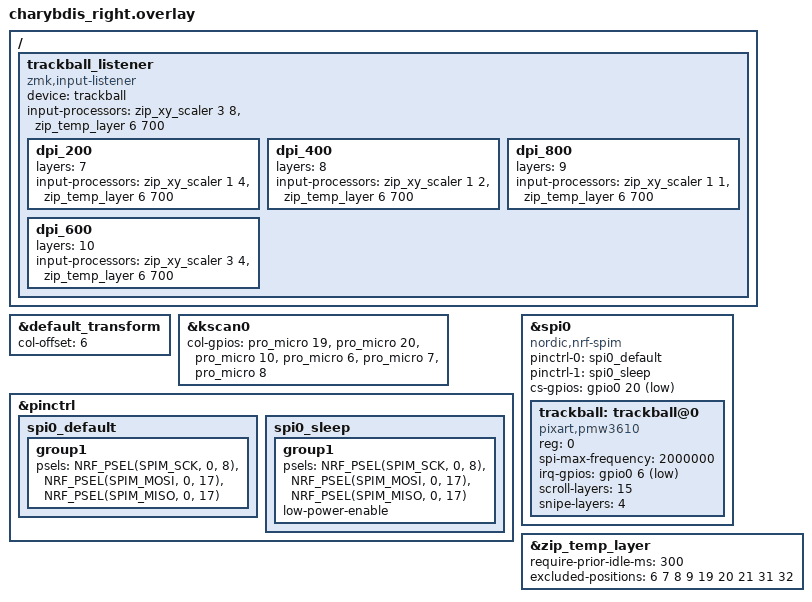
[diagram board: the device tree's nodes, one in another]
/*
 * Copyright (c) 2020 ZMK Contributors
 *
 * SPDX-License-Identifier: MIT
 */
 
#include "charybdis.dtsi"
#include <input/processors.dtsi>

&default_transform {
    col-offset = <6>;
};

&kscan0 {
	col-gpios
		= <&pro_micro 19 (GPIO_ACTIVE_HIGH | GPIO_PULL_DOWN)>
		, <&pro_micro 20 (GPIO_ACTIVE_HIGH | GPIO_PULL_DOWN)>
		, <&pro_micro 10 (GPIO_ACTIVE_HIGH | GPIO_PULL_DOWN)>
		, <&pro_micro 6 (GPIO_ACTIVE_HIGH | GPIO_PULL_DOWN)>
		, <&pro_micro 7 (GPIO_ACTIVE_HIGH | GPIO_PULL_DOWN)>
		, <&pro_micro 8 (GPIO_ACTIVE_HIGH | GPIO_PULL_DOWN)>
		;
};

// PMW3610 on the right half alongside the central. Pin/orientation values are
// retained from upstream and remain hardware assumptions to verify.
#include <dt-bindings/gpio/gpio.h>

&pinctrl {
    spi0_default: spi0_default {
        group1 {
            psels = <NRF_PSEL(SPIM_SCK, 0, 8)>,
                <NRF_PSEL(SPIM_MOSI, 0, 17)>,
                <NRF_PSEL(SPIM_MISO, 0, 17)>;
        };
    };
    spi0_sleep: spi0_sleep {
        group1 {
            psels = <NRF_PSEL(SPIM_SCK, 0, 8)>,
                <NRF_PSEL(SPIM_MOSI, 0, 17)>,
                <NRF_PSEL(SPIM_MISO, 0, 17)>;
            low-power-enable;
        };
    };
};

&spi0 {
    status = "okay";
    compatible = "nordic,nrf-spim";
    pinctrl-0 = <&spi0_default>;
    pinctrl-1 = <&spi0_sleep>;
    pinctrl-names = "default", "sleep";
    cs-gpios = <&gpio0 20 GPIO_ACTIVE_LOW>;
    trackball: trackball@0 {
        status = "okay";
        compatible = "pixart,pmw3610";
        reg = <0>;
        spi-max-frequency = <2000000>;
        irq-gpios = <&gpio0 6 (GPIO_ACTIVE_LOW | GPIO_PULL_UP)>;
        scroll-layers = <15>;
        snipe-layers = <4>;
    };
};

// Trackball input activates MSE after 300 ms without key activity and
// returns to the prior layer 700 ms after the last mouse event.
&zip_temp_layer {
    require-prior-idle-ms = <300>;
    // Logical key positions (3x12 rows, then 5 thumbs): MSE/SCR wheel
    // keys 6-9 and mouse buttons at 19-21 and 31-32.
    // Presses here do not deactivate the temp layer; they do not renew it.
    // Only mouse input events renew the 700 ms timeout.
    excluded-positions = <6 7 8 9 19 20 21 31 32>;
};

/ {
    trackball_listener {
        compatible = "zmk,input-listener";
        device = <&trackball>;
        // The scaler retains fractional motion between reports; the driver does not.
        input-processors = <&zip_xy_scaler 3 8>, <&zip_temp_layer 6 700>;

        dpi_200 {
            layers = <7>;
            input-processors = <&zip_xy_scaler 1 4>, <&zip_temp_layer 6 700>;
        };

        dpi_400 {
            layers = <8>;
            input-processors = <&zip_xy_scaler 1 2>, <&zip_temp_layer 6 700>;
        };

        dpi_800 {
            layers = <9>;
            input-processors = <&zip_xy_scaler 1 1>, <&zip_temp_layer 6 700>;
        };

        dpi_600 {
            layers = <10>;
            input-processors = <&zip_xy_scaler 3 4>, <&zip_temp_layer 6 700>;
        };
    };
};
